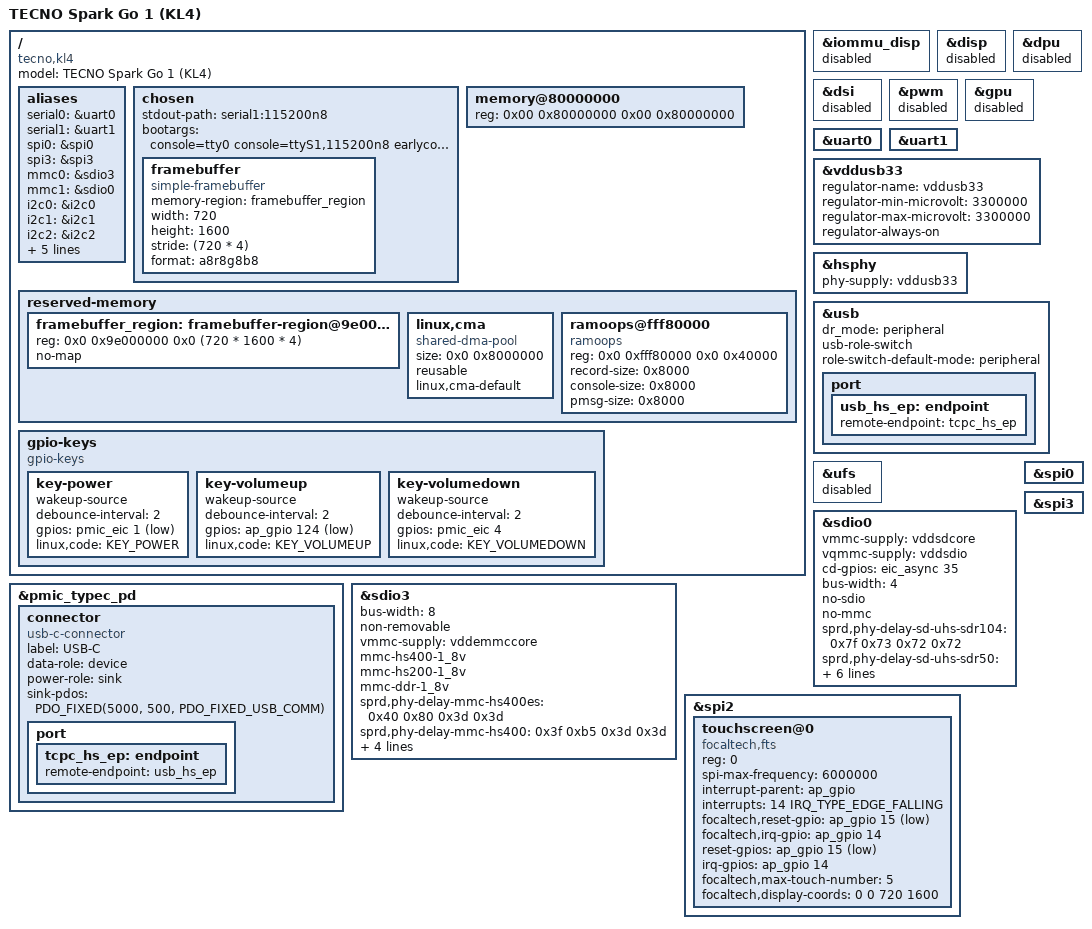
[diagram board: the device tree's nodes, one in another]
// SPDX-License-Identifier: (GPL-2.0 OR MIT)
/*
 * Copyright (C) 2026, TECNO Spark Go 1 (KL4) Mainline
 * Device tree for TECNO Spark Go 1 / UMS9230 (T615)
 */

/dts-v1/;

#include <dt-bindings/input/input.h>
#include <dt-bindings/leds/common.h>
#include <dt-bindings/usb/pd.h>
#include "ums9230.dtsi"
#include "sc2730.dtsi"

/ {
	model = "TECNO Spark Go 1 (KL4)";
	compatible = "tecno,kl4", "sprd,ums9230";

	aliases {
		serial0 = &uart0;
		serial1 = &uart1;
		spi0 = &spi0;
		spi3 = &spi3;
		mmc0 = &sdio3;
		mmc1 = &sdio0;
		i2c0 = &i2c0;
		i2c1 = &i2c1;
		i2c2 = &i2c2;
		i2c3 = &i2c3;
		i2c4 = &i2c4;
		i2c5 = &i2c5;
		i2c6 = &i2c6;
		i2c7 = &aon_i2c0;
	};

	chosen {
		#address-cells = <2>;
		#size-cells = <2>;
		ranges;

		stdout-path = "serial1:115200n8";
		bootargs = "console=tty0 console=ttyS1,115200n8 earlycon loglevel=8 ignore_loglevel clk_ignore_unused pd_ignore_unused regulator_ignore_unused init=/init pmos.debug-shell";

		framebuffer {
			compatible = "simple-framebuffer";
			memory-region = <&framebuffer_region>;
			width = <720>;
			height = <1600>;
			stride = <(720 * 4)>;
			format = "a8r8g8b8";
			status = "okay";
		};
	};

	memory@80000000 {
		device_type = "memory";
		reg = <0x00 0x80000000 0x00 0x80000000>;
	};

	reserved-memory {
		#address-cells = <2>;
		#size-cells = <2>;
		ranges;

		framebuffer_region: framebuffer-region@9e000000 {
			reg = <0x0 0x9e000000 0x0 (720 * 1600 * 4)>;
			no-map;
		};

		linux,cma {
			compatible = "shared-dma-pool";
			size = <0x0 0x8000000>;
			reusable;
			linux,cma-default;
		};

		ramoops@fff80000 {
			compatible = "ramoops";
			reg = <0x0 0xfff80000 0x0 0x40000>;
			record-size = <0x8000>;
			console-size = <0x8000>;
			pmsg-size = <0x8000>;
		};
	};

	gpio-keys {
		compatible = "gpio-keys";

		key-power {
			wakeup-source;
			debounce-interval = <2>;
			gpios = <&pmic_eic 1 GPIO_ACTIVE_LOW>;
			linux,code = <KEY_POWER>;
		};

		key-volumeup {
			wakeup-source;
			debounce-interval = <2>;
			gpios = <&ap_gpio 124 GPIO_ACTIVE_LOW>;
			linux,code = <KEY_VOLUMEUP>;
		};

		key-volumedown {
			wakeup-source;
			debounce-interval = <2>;
			gpios = <&pmic_eic 4 GPIO_ACTIVE_HIGH>;
			linux,code = <KEY_VOLUMEDOWN>;
		};
	};
};

&iommu_disp {
	status = "disabled";
};

&disp {
	status = "disabled";
};

&dpu {
	status = "disabled";
};

&dsi {
	status = "disabled";
};

&pwm {
	status = "disabled";
};

&gpu {
	status = "disabled";
};

&uart0 {
	status = "okay";
};

&uart1 {
	status = "okay";
};

&pmic_typec_pd {
	status = "okay";

	connector {
		compatible = "usb-c-connector";
		label = "USB-C";
		data-role = "device";
		power-role = "sink";
		sink-pdos = <PDO_FIXED(5000, 500, PDO_FIXED_USB_COMM)>;

		port {
			tcpc_hs_ep: endpoint {
				remote-endpoint = <&usb_hs_ep>;
			};
		};
	};
};

&vddusb33 {
	regulator-name = "vddusb33";
	regulator-min-microvolt = <3300000>;
	regulator-max-microvolt = <3300000>;
	regulator-always-on;
};

&hsphy {
	status = "okay";
	phy-supply = <&vddusb33>;
};

&usb {
	status = "okay";
	dr_mode = "peripheral";
	usb-role-switch;
	role-switch-default-mode = "peripheral";

	port {
		usb_hs_ep: endpoint {
			remote-endpoint = <&tcpc_hs_ep>;
		};
	};
};

&ufs {
	status = "disabled";
};

&sdio3 {
	status = "okay";
	bus-width = <8>;
	non-removable;
	vmmc-supply = <&vddemmccore>;
	mmc-hs400-1_8v;
	mmc-hs200-1_8v;
	mmc-ddr-1_8v;
	sprd,phy-delay-mmc-hs400es = <0x40 0x80 0x3d 0x3d>;
	sprd,phy-delay-mmc-hs400 = <0x3f 0xb5 0x3d 0x3d>;
	sprd,phy-delay-mmc-hs200 = <0x7f 0xb5 0xb5 0xb5>;
	sprd,phy-delay-mmc-ddr52 = <0x3e 0x6a 0x48 0x48>;
	sprd,phy-delay-mmc-highspeed = <0x60 0x2e 0x2c 0x2c>;
};

&sdio0 {
	status = "okay";
	vmmc-supply = <&vddsdcore>;
	vqmmc-supply = <&vddsdio>;
	cd-gpios = <&eic_async 35 GPIO_ACTIVE_HIGH>;
	bus-width = <4>;
	no-sdio;
	no-mmc;

	sprd,phy-delay-sd-uhs-sdr104 = <0x7f 0x73 0x72 0x72>;
	sprd,phy-delay-sd-uhs-sdr50 = <0x6e 0x7f 0x01 0x01>;
	sprd,phy-delay-sd-highspeed = <0x7f 0x1a 0x9a 0x9a>;
	sprd,phy-delay-legacy = <0x7f 0x1a 0x9a 0x9a>;

	sd-uhs-sdr104;
	sd-uhs-sdr50;
};

&spi0 {
	status = "okay";
};

&spi2 {
	status = "okay";
	#address-cells = <1>;
	#size-cells = <0>;

	touchscreen@0 {
		compatible = "focaltech,fts";
		reg = <0>;
		spi-max-frequency = <6000000>;
		interrupt-parent = <&ap_gpio>;
		interrupts = <14 IRQ_TYPE_EDGE_FALLING>;
		focaltech,reset-gpio = <&ap_gpio 15 GPIO_ACTIVE_LOW>;
		focaltech,irq-gpio = <&ap_gpio 14 GPIO_ACTIVE_HIGH>;
		reset-gpios = <&ap_gpio 15 GPIO_ACTIVE_LOW>;
		irq-gpios = <&ap_gpio 14 GPIO_ACTIVE_HIGH>;
		focaltech,max-touch-number = <5>;
		focaltech,display-coords = <0 0 720 1600>;
	};
};

&spi3 {
	status = "okay";
};

